AUTOSAR XML (schema 00046)
package /ComponentTypes
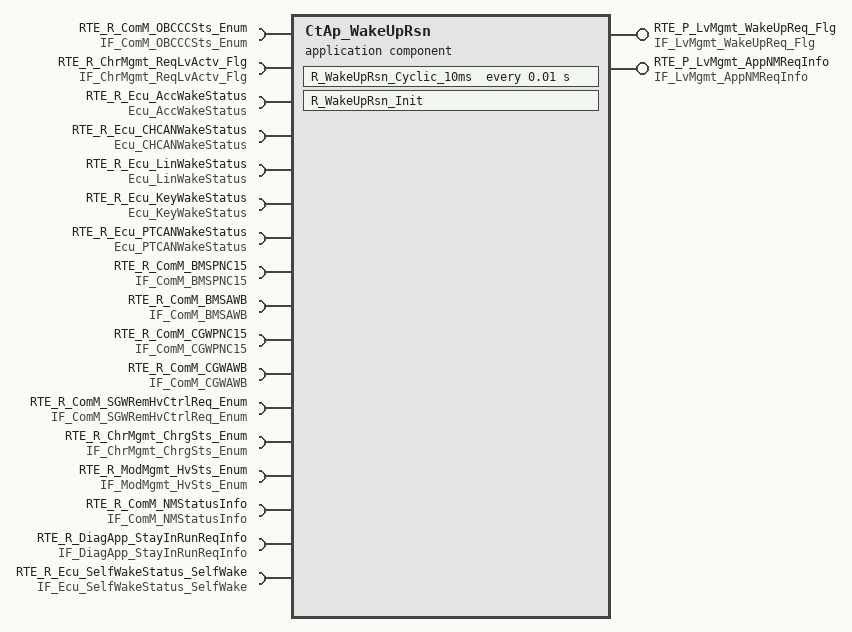
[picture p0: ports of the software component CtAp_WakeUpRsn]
  application sw component type CtAp_WakeUpRsn
    provide port RTE_P_LvMgmt_WakeUpReq_Flg: nonqueued-sender-com-spec{data-element=tec_LvMgmt_WakeUpReq_Flg, init-value=0}, provided-interface=IF_LvMgmt_WakeUpReq_Flg
    11 x require port:
      RTE_R_ComM_OBCCCSts_Enum: nonqueued-receiver-com-spec{data-element=tec_ComM_OBCCCSts_Enum, filter=data-filter-type=ALWAYS, init-value=0}, required-interface=IF_ComM_OBCCCSts_Enum
      RTE_R_ChrMgmt_ReqLvActv_Flg: nonqueued-receiver-com-spec{data-element=tec_ChrMgmt_ReqLvActv_Flg, filter=data-filter-type=ALWAYS, init-value=0}, required-interface=IF_ChrMgmt_ReqLvActv_Flg
      RTE_R_Ecu_AccWakeStatus: nonqueued-receiver-com-spec{data-element=Accwake, filter=data-filter-type=ALWAYS, init-value=0}, required-interface=Ecu_AccWakeStatus
      RTE_R_Ecu_CHCANWakeStatus: nonqueued-receiver-com-spec{data-element=CHCANwake, filter=data-filter-type=ALWAYS, init-value=0}, required-interface=Ecu_CHCANWakeStatus
      RTE_R_Ecu_LinWakeStatus: nonqueued-receiver-com-spec{data-element=Linwake, filter=data-filter-type=ALWAYS, init-value=0}, required-interface=Ecu_LinWakeStatus
      RTE_R_Ecu_KeyWakeStatus: nonqueued-receiver-com-spec{data-element=Keywake, filter=data-filter-type=ALWAYS, init-value=0}, required-interface=Ecu_KeyWakeStatus
      RTE_R_Ecu_PTCANWakeStatus: nonqueued-receiver-com-spec{data-element=PTCANwake, filter=data-filter-type=ALWAYS, init-value=0}, required-interface=Ecu_PTCANWakeStatus
      RTE_R_ComM_BMSPNC15: nonqueued-receiver-com-spec{data-element=tec_ComM_BMSPNC15, filter=data-filter-type=ALWAYS, init-value=0}, required-interface=IF_ComM_BMSPNC15
      RTE_R_ComM_BMSAWB: nonqueued-receiver-com-spec{data-element=tec_ComM_BMSAWB, filter=data-filter-type=ALWAYS, init-value=0}, required-interface=IF_ComM_BMSAWB
      RTE_R_ComM_CGWPNC15: nonqueued-receiver-com-spec{data-element=tec_ComM_CGWPNC15, filter=data-filter-type=ALWAYS, init-value=0}, required-interface=IF_ComM_CGWPNC15
      RTE_R_ComM_CGWAWB: nonqueued-receiver-com-spec{data-element=tec_ComM_CGWAWB, filter=data-filter-type=ALWAYS, init-value=0}, required-interface=IF_ComM_CGWAWB
    provide port RTE_P_LvMgmt_AppNMReqInfo: nonqueued-sender-com-spec{data-element=tec_LvMgmt_AppNMReqInfo, init-value=0}, provided-interface=IF_LvMgmt_AppNMReqInfo
    6 x require port:
      RTE_R_ComM_SGWRemHvCtrlReq_Enum: nonqueued-receiver-com-spec{data-element=tec_ComM_SGWRemHvCtrlReq_Enum, filter=data-filter-type=ALWAYS, init-value=0}, required-interface=IF_ComM_SGWRemHvCtrlReq_Enum
      RTE_R_ChrMgmt_ChrgSts_Enum: nonqueued-receiver-com-spec{data-element=tec_ChrMgmt_ChrgSts_Enum, filter=data-filter-type=ALWAYS, init-value=0}, required-interface=IF_ChrMgmt_ChrgSts_Enum
      RTE_R_ModMgmt_HvSts_Enum: nonqueued-receiver-com-spec{data-element=tec_ModMgmt_HvSts_Enum, filter=data-filter-type=ALWAYS, init-value=0}, required-interface=IF_ModMgmt_HvSts_Enum
      RTE_R_ComM_NMStatusInfo: nonqueued-receiver-com-spec{data-element=tec_ComM_NMStatusInfo, filter=data-filter-type=ALWAYS, init-value=0}, required-interface=IF_ComM_NMStatusInfo
      RTE_R_DiagApp_StayInRunReqInfo: nonqueued-receiver-com-spec{data-element=tec_DiagApp_StayInRunReqInfo, filter=data-filter-type=ALWAYS, init-value=0}, required-interface=IF_DiagApp_StayInRunReqInfo
      RTE_R_Ecu_SelfWakeStatus_SelfWake: nonqueued-receiver-com-spec{data-element=tec_Ecu_SelfWakeStatus_SelfWake, filter=data-filter-type=ALWAYS, init-value=0}, required-interface=IF_Ecu_SelfWakeStatus_SelfWake
    behavior CtAp_WakeUpRsn_InternalBehavior
      timing event TMT_R_WakeUpRsn_Cyclic_20ms: start-on-event=R_WakeUpRsn_Cyclic_10ms, period=0.01
      init event CtAp_WakeUpRsn_InitEvent: start-on-event=R_WakeUpRsn_Init
      runnable R_WakeUpRsn_Cyclic_10ms
        data-receive-point-by-arguments:
          16 x access:
            REC_RTE_R_ChrMgmt_ReqLvActv_Flg_tec_ChrMgmt_ReqLvActv_Flg: accessed-variable=RTE_R_ChrMgmt_ReqLvActv_Flg.tec_ChrMgmt_ReqLvActv_Flg
            REC_RTE_R_ComM_OBCCCSts_Enum_tec_ComM_OBCCCSts_Enum: accessed-variable=RTE_R_ComM_OBCCCSts_Enum.tec_ComM_OBCCCSts_Enum
            REC_RTE_R_ComM_BMSAWB_tec_ComM_BMSAWB: accessed-variable=RTE_R_ComM_BMSAWB.tec_ComM_BMSAWB
            REC_RTE_R_ComM_BMSPNC15_tec_ComM_BMSPNC15: accessed-variable=RTE_R_ComM_BMSPNC15.tec_ComM_BMSPNC15
            REC_RTE_R_ComM_CGWAWB_tec_ComM_CGWAWB: accessed-variable=RTE_R_ComM_CGWAWB.tec_ComM_CGWAWB
            REC_RTE_R_ComM_CGWPNC15_tec_ComM_CGWPNC15: accessed-variable=RTE_R_ComM_CGWPNC15.tec_ComM_CGWPNC15
            REC_RTE_R_Ecu_AccWakeStatus_Accwake: accessed-variable=RTE_R_Ecu_AccWakeStatus.Accwake
            REC_RTE_R_Ecu_CHCANWakeStatus_CHCANwake: accessed-variable=RTE_R_Ecu_CHCANWakeStatus.CHCANwake
            REC_RTE_R_Ecu_KeyWakeStatus_Keywake: accessed-variable=RTE_R_Ecu_KeyWakeStatus.Keywake
            REC_RTE_R_Ecu_LinWakeStatus_Linwake: accessed-variable=RTE_R_Ecu_LinWakeStatus.Linwake
            REC_RTE_R_Ecu_PTCANWakeStatus_PTCANwake: accessed-variable=RTE_R_Ecu_PTCANWakeStatus.PTCANwake
            REC_RTE_R_ComM_SGWRemHvCtrlReq_Enum_tec_ComM_SGWRemHvCtrlReq_Enum: accessed-variable=RTE_R_ComM_SGWRemHvCtrlReq_Enum.tec_ComM_SGWRemHvCtrlReq_Enum
            REC_RTE_R_ChrMgmt_ChrgSts_Enum_tec_ChrMgmt_ChrgSts_Enum: accessed-variable=RTE_R_ChrMgmt_ChrgSts_Enum.tec_ChrMgmt_ChrgSts_Enum
            REC_RTE_R_ModMgmt_HvSts_Enum_tec_ModMgmt_HvSts_Enum: accessed-variable=RTE_R_ModMgmt_HvSts_Enum.tec_ModMgmt_HvSts_Enum
            REC_RTE_R_DiagApp_StayInRunReqInfo_tec_DiagApp_StayInRunReqInfo: accessed-variable=RTE_R_DiagApp_StayInRunReqInfo.tec_DiagApp_StayInRunReqInfo
            REC_RTE_R_Ecu_SelfWakeStatus_SelfWake_tec_Ecu_SelfWakeStatus_SelfWake: accessed-variable=RTE_R_Ecu_SelfWakeStatus_SelfWake.tec_Ecu_SelfWakeStatus_SelfWake
        data-send-points:
          access SEND_RTE_P_LvMgmt_WakeUpReq_Flg_tec_LvMgmt_WakeUpReq_Flg: accessed-variable=RTE_P_LvMgmt_WakeUpReq_Flg.tec_LvMgmt_WakeUpReq_Flg
          access SEND_RTE_P_LvMgmt_AppNMReqInfo_tec_LvMgmt_AppNMReqInfo: accessed-variable=RTE_P_LvMgmt_AppNMReqInfo.tec_LvMgmt_AppNMReqInfo
      runnable R_WakeUpRsn_Init
  swc implementation CtAp_WakeUpRsn_Implementation: behavior=CtAp_WakeUpRsn_InternalBehavior
